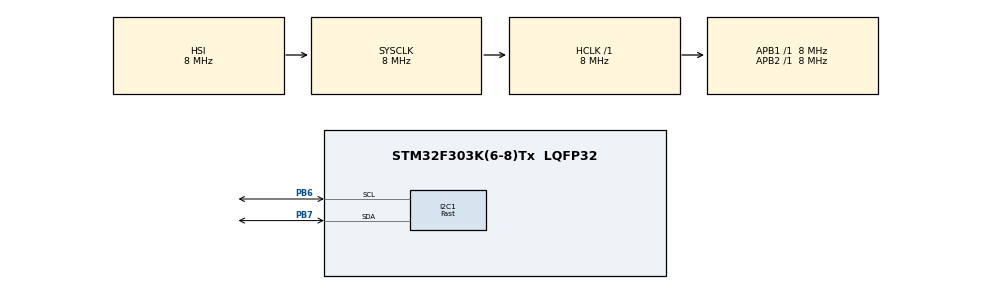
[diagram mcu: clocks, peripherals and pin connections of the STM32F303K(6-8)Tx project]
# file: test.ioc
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Dma.I2C1_RX.0.Direction=DMA_PERIPH_TO_MEMORY
Dma.I2C1_RX.0.Instance=DMA1_Channel3
Dma.I2C1_RX.0.MemDataAlignment=DMA_MDATAALIGN_BYTE
Dma.I2C1_RX.0.MemInc=DMA_MINC_ENABLE
Dma.I2C1_RX.0.Mode=DMA_NORMAL
Dma.I2C1_RX.0.PeriphDataAlignment=DMA_PDATAALIGN_BYTE
Dma.I2C1_RX.0.PeriphInc=DMA_PINC_DISABLE
Dma.I2C1_RX.0.Priority=DMA_PRIORITY_LOW
Dma.I2C1_TX.1.Direction=DMA_MEMORY_TO_PERIPH
Dma.I2C1_TX.1.Instance=DMA1_Channel2
Dma.I2C1_TX.1.MemDataAlignment=DMA_MDATAALIGN_BYTE
Dma.I2C1_TX.1.MemInc=DMA_MINC_ENABLE
Dma.I2C1_TX.1.Mode=DMA_NORMAL
Dma.I2C1_TX.1.PeriphDataAlignment=DMA_PDATAALIGN_BYTE
Dma.I2C1_TX.1.PeriphInc=DMA_PINC_DISABLE
Dma.I2C1_TX.1.Priority=DMA_PRIORITY_LOW
Dma.Request0=I2C1_RX
Dma.Request1=I2C1_TX
I2C1.I2C_Speed_Mode=I2C_Fast
I2C1.Timing=0x0010020A
Mcu.Family=STM32F3
Mcu.Name=STM32F303K(6-8)Tx
Mcu.Package=LQFP32
NVIC.DMA1_Channel2_IRQn=true\:0\:0\:false\:false\:true\:false\:true\:true
NVIC.DMA1_Channel3_IRQn=true\:0\:0\:false\:false\:true\:false\:true\:true
NVIC.I2C1_EV_IRQn=true\:0\:0\:false\:false\:true\:true\:true\:true
NVIC.PriorityGroup=NVIC_PRIORITYGROUP_4
PB6.GPIO_Pu=GPIO_PULLUP
PB6.Mode=I2C
PB6.Signal=I2C1_SCL
PB7.GPIO_Pu=GPIO_PULLUP
PB7.Mode=I2C
PB7.Signal=I2C1_SDA
ProjectManager.HeapSize=0x200
ProjectManager.StackSize=0x400
ProjectManager.TargetToolchain=STM32CubeIDE
RCC.AHBFreq_Value=8000000
RCC.APB1Freq_Value=8000000
RCC.APB2Freq_Value=8000000
RCC.CortexFreq_Value=8000000
RCC.HSE_VALUE=8000000
RCC.HSI_VALUE=8000000
RCC.SYSCLKFreq_VALUE=8000000
board=custom

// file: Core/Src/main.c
/* USER CODE BEGIN Header */
/**
 ******************************************************************************
 * @file           : main.c
 * @brief          : Main program body
 ******************************************************************************
 * @attention
 *
 * Copyright (c) 2025 STMicroelectronics.
 * All rights reserved.
 *
 * This software is licensed under terms that can be found in the LICENSE file
 * in the root directory of this software component.
 * If no LICENSE file comes with this software, it is provided AS-IS.
 *
 ******************************************************************************
 */
/* USER CODE END Header */
#include "main.h"

/* USER CODE BEGIN PD */
#define MPU6050_ADDR_LSL1	0xD0
/* USER CODE END PD */

I2C_HandleTypeDef hi2c1;
DMA_HandleTypeDef hdma_i2c1_rx;
DMA_HandleTypeDef hdma_i2c1_tx;

/* USER CODE BEGIN PV */
uint8_t i2c_RX_done = 0;
uint8_t i2c_TX_done = 0;
/* USER CODE END PV */

void SystemClock_Config(void);
static void MX_GPIO_Init(void);
static void MX_DMA_Init(void);
static void MX_I2C1_Init(void);
/* USER CODE BEGIN PFP */
HAL_StatusTypeDef i2c_Write_Accelerometer(I2C_HandleTypeDef *hi2c, uint16_t DevAddress, uint8_t MemAddress, uint8_t *pData, uint16_t len); // <-- Add this line here
HAL_StatusTypeDef i2c_Read_Accelerometer(I2C_HandleTypeDef *hi2c, uint16_t DevAddress, uint8_t regAddress, uint8_t *pData, uint16_t len);
/* USER CODE END PFP */

int main(void)
{

	/* MCU Configuration--------------------------------------------------------*/

	/* Reset of all peripherals, Initializes the Flash interface and the Systick. */
	HAL_Init();

	/* Configure the system clock */
	SystemClock_Config();

	/* Initialize all configured peripherals */
	MX_GPIO_Init();
	MX_DMA_Init();
	MX_I2C1_Init();
	/* USER CODE BEGIN 2 */
//	HAL_NVIC_EnableIRQ(I2C1_EV_IRQn);
//	__HAL_DMA_ENABLE(&hdma_i2c1_tx);
//	__HAL_DMA_ENABLE(&hdma_i2c1_rx);
//	__HAL_DMA_ENABLE_IT(&hdma_i2c1_tx, DMA_IT_TC | DMA_IT_HT);
//	__enable_irq();
	//const char wmsg[]="WeloveSTM32!";
	uint8_t angle_data[] =
	{ 0x00, 0x00 }; //Angle data buffer, read angle data into this buffer and also write to registers with this buffer for programming
	uint8_t rmsg[20]; //received message buffer, randomly used

	//HAL i2c notes:
	//address of MPU6050 device is 1101000, but we shift it to left because the transmit and receive functions require that. So we are left with 0xD0
	//Argument to right of MPU6050_ADDR_LSL1 is the register address, see the register description in onenote.
	uint8_t addr[2];
	/* We compute the MSB and LSB parts of the memory address */
	addr[0] = (uint8_t) (0x6A);
	addr[1] = (uint8_t) (0x6B);
	addr[2] = (uint8_t) (0x6B);
	addr[3] = (uint8_t) (0x6B);
	addr[4] = (uint8_t) (0x6B);
	addr[5] = (uint8_t) (0x6B);
	addr[6] = (uint8_t) (0x6B);
	addr[7] = (uint8_t) (0x6B);
	addr[8] = (uint8_t) (0x6B);
	addr[9] = (uint8_t) (0x6B);
	HAL_I2C_StateTypeDef state = HAL_I2C_GetState(&hi2c1);

	HAL_StatusTypeDef returnValue = HAL_I2C_Master_Transmit_DMA(&hi2c1, MPU6050_ADDR_LSL1, addr, 1);
	while (!i2c_TX_done);
	i2c_TX_done = 0;
	state = HAL_I2C_GetState(&hi2c1);
	if (returnValue != HAL_OK)
	{
		Error_Handler();
	}
	state = HAL_I2C_GetState(&hi2c1);
//	while (HAL_I2C_GetState(&hi2c1) != HAL_I2C_STATE_READY);

//	if (__HAL_DMA_GET_FLAG(&hdma_i2c1_tx, (0x00000002U)))
//	{  // Transfer error
//		printf("DMA Transfer Error\n");
//		// Handle error here
//	}
//	HAL_DMA_IRQHandler(&hdma_i2c1_tx);
//	I2C1_EV_IRQHandler();
//	HAL_NVIC_EnableIRQ(I2C1_EV_IRQn);

	state = HAL_I2C_GetState(&hi2c1);

	returnValue = HAL_I2C_Master_Transmit_IT(&hi2c1, MPU6050_ADDR_LSL1, addr, 1);
	while (!i2c_TX_done);
	i2c_TX_done = 0;
	state = HAL_I2C_GetState(&hi2c1);
	/* USER CODE END 2 */

	/* Infinite loop */
	while (1)
	{

	}
}

void SystemClock_Config(void)
{
	RCC_OscInitTypeDef RCC_OscInitStruct =
	{ 0 };
	RCC_ClkInitTypeDef RCC_ClkInitStruct =
	{ 0 };
	RCC_PeriphCLKInitTypeDef PeriphClkInit =
	{ 0 };

	/** Initializes the RCC Oscillators according to the specified parameters
	 * in the RCC_OscInitTypeDef structure.
	 */
	RCC_OscInitStruct.OscillatorType = RCC_OSCILLATORTYPE_HSI;
	RCC_OscInitStruct.HSIState = RCC_HSI_ON;
	RCC_OscInitStruct.HSICalibrationValue = RCC_HSICALIBRATION_DEFAULT;
	RCC_OscInitStruct.PLL.PLLState = RCC_PLL_NONE;
	if (HAL_RCC_OscConfig(&RCC_OscInitStruct) != HAL_OK)
	{
		Error_Handler();
	}

	/** Initializes the CPU, AHB and APB buses clocks
	 */
	RCC_ClkInitStruct.ClockType = RCC_CLOCKTYPE_HCLK | RCC_CLOCKTYPE_SYSCLK | RCC_CLOCKTYPE_PCLK1 | RCC_CLOCKTYPE_PCLK2;
	RCC_ClkInitStruct.SYSCLKSource = RCC_SYSCLKSOURCE_HSI;
	RCC_ClkInitStruct.AHBCLKDivider = RCC_SYSCLK_DIV1;
	RCC_ClkInitStruct.APB1CLKDivider = RCC_HCLK_DIV1;
	RCC_ClkInitStruct.APB2CLKDivider = RCC_HCLK_DIV1;

	if (HAL_RCC_ClockConfig(&RCC_ClkInitStruct, FLASH_LATENCY_0) != HAL_OK)
	{
		Error_Handler();
	}
	PeriphClkInit.PeriphClockSelection = RCC_PERIPHCLK_I2C1;
	PeriphClkInit.I2c1ClockSelection = RCC_I2C1CLKSOURCE_HSI;
	if (HAL_RCCEx_PeriphCLKConfig(&PeriphClkInit) != HAL_OK)
	{
		Error_Handler();
	}
}

static void MX_I2C1_Init(void)
{

	hi2c1.Instance = I2C1;
	hi2c1.Init.Timing = 0x0010020A;
	hi2c1.Init.OwnAddress1 = 0;
	hi2c1.Init.AddressingMode = I2C_ADDRESSINGMODE_7BIT;
	hi2c1.Init.DualAddressMode = I2C_DUALADDRESS_DISABLE;
	hi2c1.Init.OwnAddress2 = 0;
	hi2c1.Init.OwnAddress2Masks = I2C_OA2_NOMASK;
	hi2c1.Init.GeneralCallMode = I2C_GENERALCALL_DISABLE;
	hi2c1.Init.NoStretchMode = I2C_NOSTRETCH_DISABLE;
	if (HAL_I2C_Init(&hi2c1) != HAL_OK)
	{
		Error_Handler();
	}

	/** Configure Analogue filter
	 */
	if (HAL_I2CEx_ConfigAnalogFilter(&hi2c1, I2C_ANALOGFILTER_ENABLE) != HAL_OK)
	{
		Error_Handler();
	}

	/** Configure Digital filter
	 */
	if (HAL_I2CEx_ConfigDigitalFilter(&hi2c1, 0) != HAL_OK)
	{
		Error_Handler();
	}

}

static void MX_DMA_Init(void)
{

	/* DMA controller clock enable */
	__HAL_RCC_DMA1_CLK_ENABLE();

	/* DMA interrupt init */
	/* DMA1_Channel2_IRQn interrupt configuration */
	HAL_NVIC_SetPriority(DMA1_Channel2_IRQn, 0, 0);
	HAL_NVIC_EnableIRQ(DMA1_Channel2_IRQn);
	/* DMA1_Channel3_IRQn interrupt configuration */
	HAL_NVIC_SetPriority(DMA1_Channel3_IRQn, 0, 0);
	HAL_NVIC_EnableIRQ(DMA1_Channel3_IRQn);

}

static void MX_GPIO_Init(void)
{

	/* GPIO Ports Clock Enable */
	__HAL_RCC_GPIOB_CLK_ENABLE();

}

/* USER CODE BEGIN 4 */
HAL_StatusTypeDef i2c_Read_Accelerometer(I2C_HandleTypeDef *hi2c, uint16_t DevAddress, uint8_t regAddress, uint8_t *pData, uint16_t len)
{
	HAL_StatusTypeDef returnValue;
	uint8_t addr[1];

	/* We compute the MSB and LSB parts of the memory address */
	addr[0] = (uint8_t) (regAddress);

	/* First we send the memory location address where start reading data */
//	returnValue = HAL_I2C_Master_Seq_Transmit_DMA(hi2c, DevAddress, addr, 1, I2C_FIRST_FRAME);
	returnValue = HAL_I2C_Master_Transmit_DMA(hi2c, DevAddress, addr, 1);
	uint32_t i2c_error = HAL_I2C_GetError(&hi2c1);
	while (!i2c_TX_done);
	i2c_TX_done = 0;

	/* Next we can retrieve the data from EEPROM */
	returnValue = HAL_I2C_Master_Seq_Receive_DMA(hi2c, DevAddress, pData, len, I2C_LAST_FRAME);
	while (!i2c_TX_done);
	i2c_TX_done = 0;
	return returnValue;
}

HAL_StatusTypeDef i2c_Write_Accelerometer(I2C_HandleTypeDef *hi2c, uint16_t DevAddress, uint8_t regAddress, uint8_t *pData, uint16_t len)
{
	HAL_StatusTypeDef returnValue;
	uint8_t *data;

	data = (uint8_t*) malloc(sizeof(uint8_t));
	/*We compute the MSB and LSB parts of the memory address*/
	data[0] = (uint8_t) (regAddress);

	/*And copy the content of the pData array in the temporary buffer*/
	memcpy(data + 1, pData, len); //inserts data one slot after the register address

	/*We are now ready to transfer the buffer over the I2C bus*/
	returnValue = HAL_I2C_Master_Transmit_DMA(hi2c, DevAddress, data, len + 1);

	free(data);
	/*We wait until the Accelerometer effectively stores data*/
	while (HAL_I2C_Master_Transmit(hi2c, DevAddress, 0, 0, HAL_MAX_DELAY) != HAL_OK); //peripheral can only accept the transmission once it finishes doing what it does

	return HAL_OK;
}
void HAL_I2C_MasterTxCpltCallback(I2C_HandleTypeDef *hi2c)
{
	i2c_TX_done = 1;
}
void HAL_I2C_MasterRxCpltCallback(I2C_HandleTypeDef *hi2c)
{
	i2c_RX_done = 1;
}
//void I2C1_EV_IRQHandler(void)
//{
//	HAL_I2C_EV_IRQHandler(&hi2c1);
//}
/* USER CODE END 4 */

void Error_Handler(void)
{
	__disable_irq();
	while (1)
	{
	}
}
